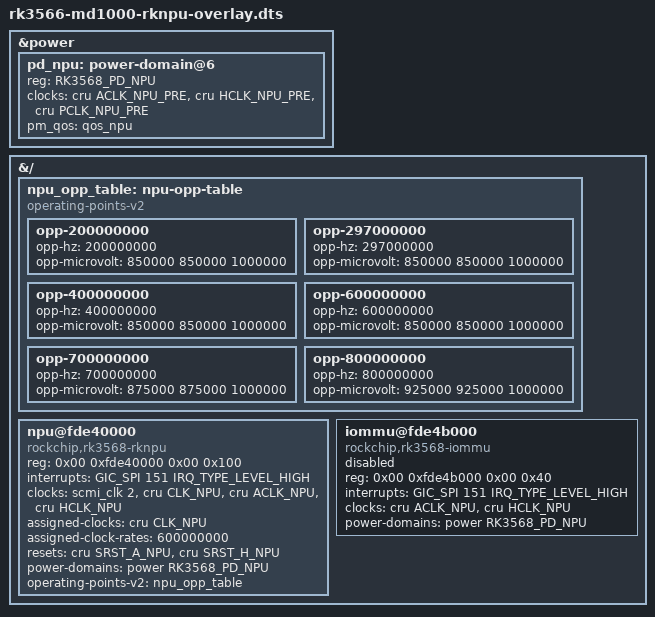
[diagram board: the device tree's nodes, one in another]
// SPDX-License-Identifier: (GPL-2.0+ OR MIT)
/*
 * DT overlay for RK3566 NPU support on Inspur MD1000.
 *
 * Derived from codex's rk3566-rknpu-overlay.dts (kept unmodified).
 * MD1000-specific differences (do not change codex's original):
 *   1. SCMI clock: this ophub kernel's rk3568-cru.h names the NPU
 *      SCMI clock index SCMI_CLK_NPU2 (value 2), not SCMI_CLK_NPU.
 *   2. The base MD1000 DTB does not describe the NPU rail. Apply
 *      rk3566-md1000-npu-dvfs afterwards to bind the RK809 supply
 *      and select the validated OPPs.
 *
 * Compile (same commands as the Makefile dtbo target, but KDIR must
 * point at the headers ROOT so that include/dt-bindings resolves):
 *   cpp -nostdinc -I /usr/src/linux-headers-$(uname -r)/include \
 *       -undef -x assembler-with-cpp rk3566-md1000-rknpu-overlay.dts \
 *       rk3566-md1000-rknpu-overlay.dts.preprocessed
 *   dtc -@ -I dts -O dtb -o rk3566-md1000-rknpu.dtbo \
 *       rk3566-md1000-rknpu-overlay.dts.preprocessed
 */

/dts-v1/;
/plugin/;

#include <dt-bindings/clock/rk3568-cru.h>
#include <dt-bindings/interrupt-controller/arm-gic.h>
#include <dt-bindings/interrupt-controller/irq.h>
#include <dt-bindings/power/rk3568-power.h>

/* 1. NPU power domain ------------------------------------------------- */

&power {
pd_npu: power-domain@6 {
reg = <RK3568_PD_NPU>;
clocks = <&cru ACLK_NPU_PRE>,
 <&cru HCLK_NPU_PRE>,
 <&cru PCLK_NPU_PRE>;
pm_qos = <&qos_npu>;
#power-domain-cells = <0>;
};
};

/* 2. NPU device, IOMMU, and OPP table (root-level nodes) ------------- */

&{/} {
npu_opp_table: npu-opp-table {
compatible = "operating-points-v2";

opp-200000000 {
opp-hz = /bits/ 64 <200000000>;
opp-microvolt = <850000 850000 1000000>;
};
opp-297000000 {
opp-hz = /bits/ 64 <297000000>;
opp-microvolt = <850000 850000 1000000>;
};
opp-400000000 {
opp-hz = /bits/ 64 <400000000>;
opp-microvolt = <850000 850000 1000000>;
};
opp-600000000 {
opp-hz = /bits/ 64 <600000000>;
opp-microvolt = <850000 850000 1000000>;
};
opp-700000000 {
opp-hz = /bits/ 64 <700000000>;
opp-microvolt = <875000 875000 1000000>;
};
opp-800000000 {
opp-hz = /bits/ 64 <800000000>;
opp-microvolt = <925000 925000 1000000>;
};
};

npu@fde40000 {
compatible = "rockchip,rk3568-rknpu", "rockchip,rknpu";
/* vendor rk356x reg window is 0x100; 0x10000 would overlap the NPU iommu @fde4b000 */
reg = <0x00 0xfde40000 0x00 0x100>;
interrupts = <GIC_SPI 151 IRQ_TYPE_LEVEL_HIGH>;
interrupt-names = "npu_irq";
clocks = <&scmi_clk 2>,
 <&cru CLK_NPU>,
 <&cru ACLK_NPU>,
 <&cru HCLK_NPU>;
clock-names = "scmi_clk", "clk", "aclk", "hclk";
assigned-clocks = <&cru CLK_NPU>;
/* Mirror the MD1000 boot clock on the CRU. */
assigned-clock-rates = <600000000>;
resets = <&cru SRST_A_NPU>, <&cru SRST_H_NPU>;
reset-names = "srst_a", "srst_h";
power-domains = <&power RK3568_PD_NPU>;
operating-points-v2 = <&npu_opp_table>;
status = "okay";
};

/*
 * The companion rk3566-md1000-npu-iommu-fix overlay attaches this
 * IOMMU after the base NPU node has been created.
 */
iommu@fde4b000 {
compatible = "rockchip,rk3568-iommu";
reg = <0x00 0xfde4b000 0x00 0x40>;
interrupts = <GIC_SPI 151 IRQ_TYPE_LEVEL_HIGH>;
interrupt-names = "rknpu_mmu";
clocks = <&cru ACLK_NPU>, <&cru HCLK_NPU>;
clock-names = "aclk", "iface";
power-domains = <&power RK3568_PD_NPU>;
#iommu-cells = <0>;
status = "disabled";
};
};
